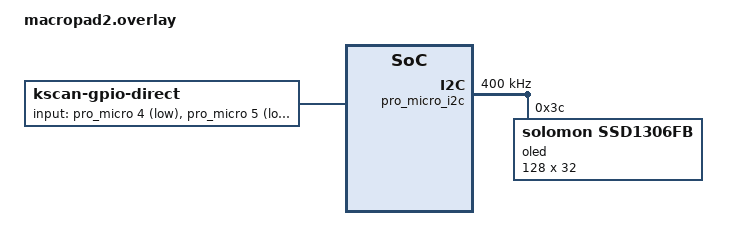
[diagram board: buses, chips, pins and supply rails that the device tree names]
#include <dt-bindings/zmk/matrix_transform.h>

#include "macropad2-layouts.dtsi"

/ {
    chosen {
        zmk,physical-layout = &default_layout;
        zephyr,display = &oled;
    };

    // Direct wiring: each key goes from its own pin to GND, no diodes needed.
    kscan: kscan {
        compatible = "zmk,kscan-gpio-direct";
        wakeup-source;

        input-gpios
            = <&pro_micro 4 (GPIO_ACTIVE_LOW | GPIO_PULL_UP)>   // key 1: pin labeled 022 (P0.22)
            , <&pro_micro 5 (GPIO_ACTIVE_LOW | GPIO_PULL_UP)>   // key 2: pin labeled 024 (P0.24)
            ;
    };

    // Direct wiring reports every key as row 0, column N.
    default_transform: default_transform {
        compatible = "zmk,matrix-transform";
        columns = <2>;
        rows = <1>;
        map = <
            RC(0, 0) RC(0, 1)
        >;
    };
};

// 0.91" 128x32 SSD1306 OLED. SDA -> pin 017, SCK -> pin 020.
&pro_micro_i2c {
    status = "okay";
    clock-frequency = <400000>; // 400 kHz fast mode, so full-screen animation frames send quickly

    oled: ssd1306@3c {
        compatible = "solomon,ssd1306fb";
        reg = <0x3c>;
        width = <128>;
        height = <32>;
        segment-offset = <0>;
        page-offset = <0>;
        display-offset = <0>;
        multiplex-ratio = <31>;
        segment-remap;
        com-invdir;
        com-sequential;
        inversion-on;
        prechargep = <0x22>;
    };
};
